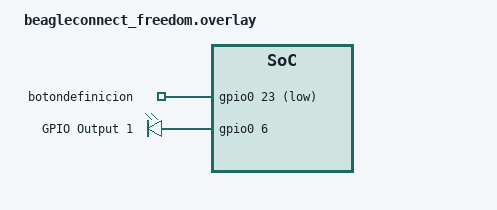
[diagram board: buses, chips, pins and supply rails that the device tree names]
/ {
    aliases {
        miboton = &botondefinicion;
        salidadigital = &gpio_out1;
    };

    gpio_keys {
        compatible = "gpio-keys";
        botondefinicion: primerboton {
            gpios = <&gpio0 23 GPIO_ACTIVE_LOW>;
        };
    };

    gpio_outs: salidas {
        compatible = "gpio-leds";

        gpio_out1: gpio_out1 {
            gpios = <&gpio0 6 GPIO_ACTIVE_HIGH>;  // DIO19
            label = "GPIO Output 1";
        };

    };
    
};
